# STM32L081xx register map
File version: 1.0
Registers are 32-bit, read-write, reset 0x0 unless marked. A register's access mark holds for its fields unless they carry their own. Offsets are from the block's base; [hi:lo] are bit positions; {n}, {i} and the like mark numbered series.

## FLASH — FLASH Registers
Base 0x40022000
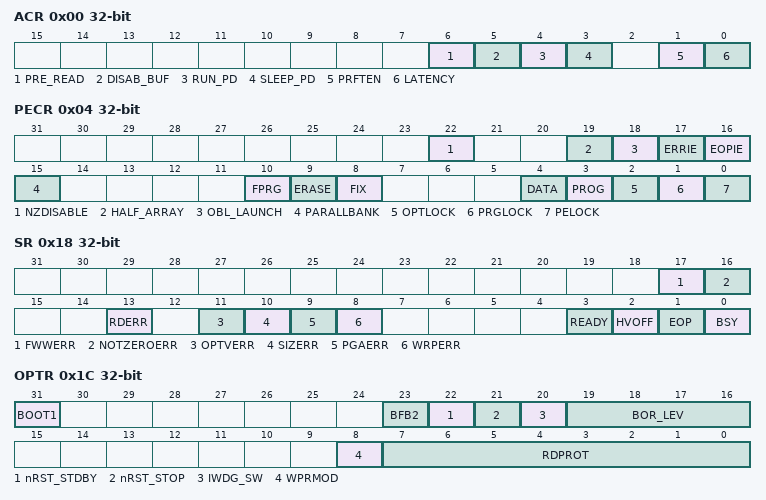
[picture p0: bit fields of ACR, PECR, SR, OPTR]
0x00 ACR — Access control register
  [6] PRE_READ — Pre-read data address
  [5] DISAB_BUF — Disable Buffer
  [4] RUN_PD — Flash mode during RUN mode
  [3] SLEEP_PD — Flash mode during sleep mode
  [1] PRFTEN — Prefetch Buffer Enable
  [0] LATENCY — LATENCY bit (Latency)
    0=FLASH Zero Latency cycle; 1=FLASH One Latency cycle
0x04 PECR — Program/erase control register
  [22] NZDISABLE — Non-Zero check disable
  [19] HALF_ARRAY — Half array mode
  [18] OBL_LAUNCH — Launch the option byte loading
  [17] ERRIE — Error interrupt
  [16] EOPIE — End of programming interrupt
  [15] PARALLBANK — Parallel Bank mode
  [10] FPRG — Fast Page/Half Page programming mode
  [9] ERASE — Page erasing mode
  [8] FIX — Fixed Time Data write for Word/Half Word/Byte programming
  [4] DATA — Data matrix selection
  [3] PROG — Program matrix selection
  [2] OPTLOCK — Option byte matrix Lock
  [1] PRGLOCK — Program matrix Lock
  [0] PELOCK — FLASH_PECR and Flash data Lock
0x08 PDKEYR — Power down key register
  [31:0] PDKEYR — FLASH_PEC and data matrix Key
0x0C PEKEYR — Program/erase key register
  [31:0] PEKEYR — FLASH_PEC and data matrix Key
0x10 PRGKEYR — Program memory key register
  [31:0] PRGKEYR — Program matrix Key
0x14 OPTKEYR — Option byte key register
  [31:0] OPTKEYR — Option bytes matrix Key
0x18 SR — Status register
  [17] FWWERR — Write/Errase operation aborted
  [16] NOTZEROERR — Not Zero error
  [13] RDERR — Read protected error
  [11] OPTVERR — Option Valid error
  [10] SIZERR — Size error
  [9] PGAERR — Programming Alignment Error
  [8] WRPERR — Write protection error
  [3] READY — Flash ready after low power mode
  [2] HVOFF — End of high voltage
  [1] EOP — End Of Programming
  [0] BSY — Busy
0x1C OPTR — Option byte register
  [31] BOOT1
  [23] BFB2
  [22] nRST_STDBY
  [21] nRST_STOP
  [20] IWDG_SW
  [19:16] BOR_LEV — BOR_LEV[3:0] Brown Out Reset Threshold Level
  [8] WPRMOD — Selection of protection mode of WPR bits
  [7:0] RDPROT — Read Protection
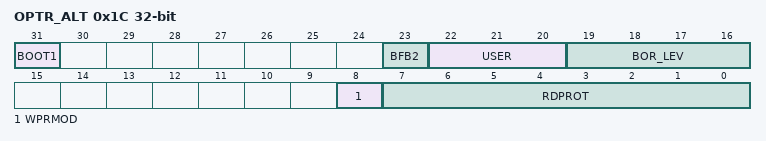
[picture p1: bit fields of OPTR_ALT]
0x1C OPTR_ALT (alternate view of OPTR) — Option byte register
  [31] BOOT1
  [23] BFB2
  [22:20] USER — User Option Bytes
  [19:16] BOR_LEV — BOR_LEV[3:0] Brown Out Reset Threshold Level
  [8] WPRMOD — Selection of protection mode of WPR bits
  [7:0] RDPROT — Read Protection
0x20 WRPR — Write protection register
  [15:0] WRP — Write Protection bits
0x80 WRPR2 — Write protection register 2
  [15:0] WRP — Write Protection bits

## CRC — CRC calculation unit
Base 0x40023000
0x00 DR — CRC Data register
  [31:0] DR — Data register bits
0x04 IDR 8-bit — CRC Independent data register
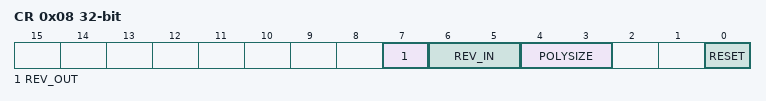
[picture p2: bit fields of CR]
0x08 CR — CRC Control register
  [7] REV_OUT — REV_OUT Reverse Output Data bits
    0=NONE (Output Data bit order not affected); 1=BIT (Output Data bit reversal done by bit)
  [6:5] REV_IN — REV_IN Reverse Input Data bits
    0=NONE (Input Data bit order not affected); 1=BYTE (Input Data bit reversal done by byte); 2=HALFWORD (Input Data bit reversal done by half-word); 3=WORD (Input Data bit reversal done by word)
  [4:3] POLYSIZE — Polynomial size bits
    0=POLYLENGTH_32B (32 bits Polynomial size); 1=POLYLENGTH_16B (16 bits Polynomial size); 2=POLYLENGTH_8B (8 bits Polynomial size); 3=POLYLENGTH_7B (7 bits Polynomial size)
  [0] RESET — RESET the CRC computation unit bit
0x10 INIT — Initial CRC value register
  [31:0] INIT — Initial CRC value bits
0x14 POL — CRC polynomial register
  [31:0] POL — Coefficients of the polynomial

## AES — AES hardware accelerator
Base 0x40026000
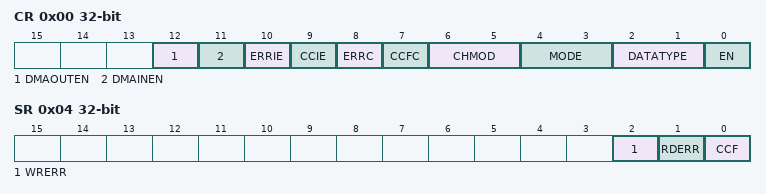
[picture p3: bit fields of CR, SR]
0x00 CR — AES control register
  [12] DMAOUTEN — DMA Enable managing the data output phase
  [11] DMAINEN — DMA ENable managing the data input phase
  [10] ERRIE — Error Interrupt Enable
  [9] CCIE — Computation Complete Interrupt Enable
  [8] ERRC — Error Clear
  [7] CCFC — Computation Complete Flag Clear
  [6:5] CHMOD — AES Chaining Mode
  [4:3] MODE — AES Mode Of Operation
  [2:1] DATATYPE — Data type selection
  [0] EN — AES Enable
0x04 SR — AES status register
  [2] WRERR — Write Error Flag
  [1] RDERR — Read Error Flag
  [0] CCF — Computation Complete Flag
0x08 DINR — AES data input register
  [15:0] DINR — AES Data Input Register
0x0C DOUTR — AES data output register
  [15:0] DOUTR — AES Data Output Register
{0x10+4i} KEYR{i} (i=0..3) — AES key register {i}
  [15:0] KEYR{i} — AES Key Register {i}
{0x20+4i} IVR{i} (i=0..3) — AES initialization vector register {i}
  [15:0] IVR{i} — AES Initialization Vector Register {i}

## GPIOA — General Purpose IO
Base 0x50000000
Same registers: GPIOB 0x50000400, GPIOC 0x50000800, GPIOD 0x50000C00, GPIOE 0x50001000, GPIOH 0x50001C00
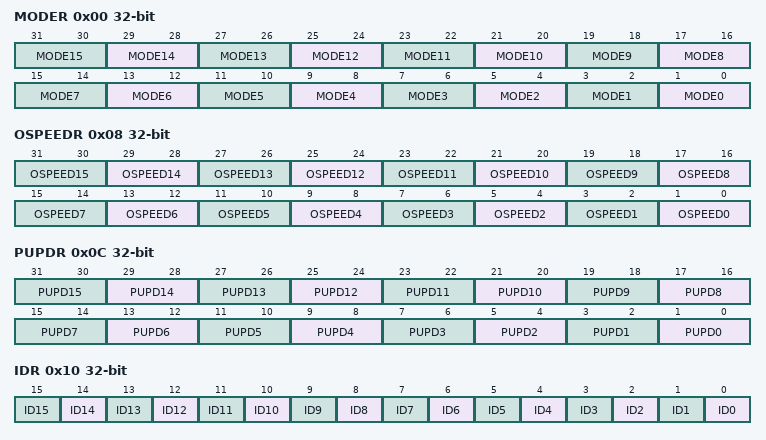
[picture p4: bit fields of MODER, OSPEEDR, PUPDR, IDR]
0x00 MODER — GPIO port mode register
  [2n+1:2n] MODE{n} (n=0..15)
0x04 OTYPER — GPIO port output type register
0x08 OSPEEDR — GPIO port output speed register
  [2n+1:2n] OSPEED{n} (n=0..15)
0x0C PUPDR — GPIO port pull-up/pull-down register
  [2n+1:2n] PUPD{n} (n=0..15)
0x10 IDR — GPIO port input data register
  [n] ID{n} (n=0..15)
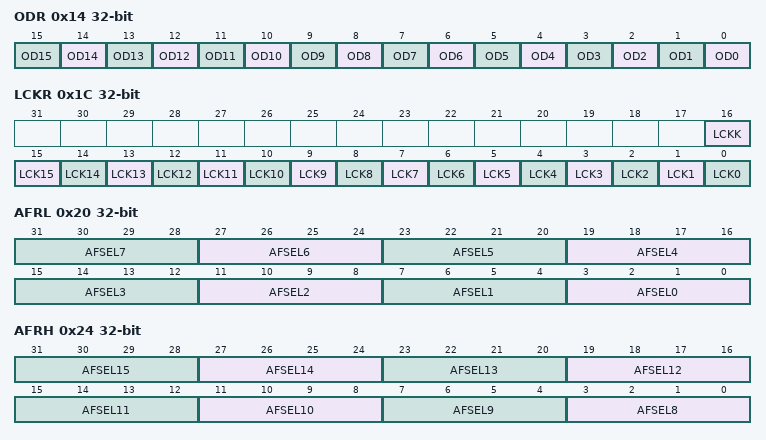
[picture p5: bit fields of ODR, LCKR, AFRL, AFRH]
0x14 ODR — GPIO port output data register
  [n] OD{n} (n=0..15)
0x18 BSRR — GPIO port bit set/reset registerBSRR
0x1C LCKR — GPIO port configuration lock register
  [16] LCKK, [n] LCK{n} (n=0..15)
0x20 AFRL — GPIO alternate function register
  [4n+3:4n] AFSEL{n} (n=0..7)
0x24 AFRH — GPIO alternate function register
  [4n-29:4n-32] AFSEL{n} (n=8..15)
0x28 BRR — GPIO bit reset register
